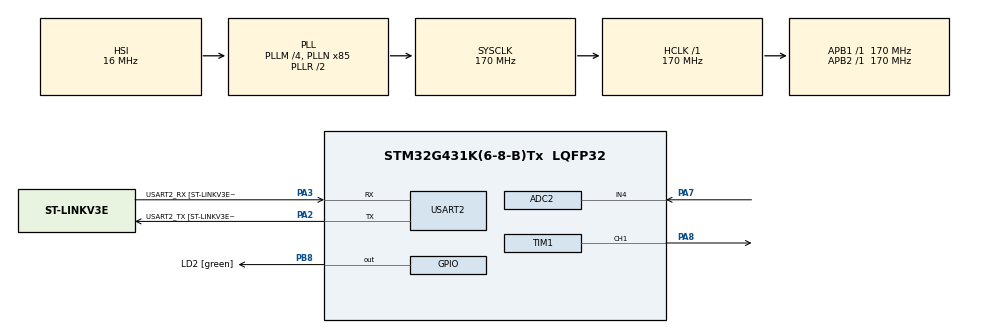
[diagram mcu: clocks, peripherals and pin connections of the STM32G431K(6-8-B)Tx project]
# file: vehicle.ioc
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ADC2.Channel-0\#ChannelRegularConversion=ADC_CHANNEL_4
ADC2.ClockPrescaler=ADC_CLOCK_ASYNC_DIV256
ADC2.ContinuousConvMode=ENABLE
ADC2.ExternalTrigConv=ADC_EXTERNALTRIG_T1_TRGO
ADC2.ExternalTrigConvEdge=ADC_EXTERNALTRIGCONVEDGE_FALLING
ADC2.NbrOfConversionFlag=1
ADC2.OffsetNumber-0\#ChannelRegularConversion=ADC_OFFSET_NONE
ADC2.Rank-0\#ChannelRegularConversion=1
ADC2.SamplingTime-0\#ChannelRegularConversion=ADC_SAMPLETIME_2CYCLES_5
Mcu.Family=STM32G4
Mcu.Name=STM32G431K(6-8-B)Tx
Mcu.Package=LQFP32
NVIC.PriorityGroup=NVIC_PRIORITYGROUP_4
PA13.GPIO_Label=T_SWDIO
PA13.Mode=Serial_Wire
PA13.Signal=SYS_JTMS-SWDIO
PA14.GPIO_Label=T_SWCLK
PA14.Mode=Serial_Wire
PA14.Signal=SYS_JTCK-SWCLK
PA2.GPIO_Label=USART2_TX [ST-LINKV3E_VCP_RX]
PA2.Mode=Asynchronous
PA2.Signal=USART2_TX
PA3.GPIO_Label=USART2_RX [ST-LINKV3E_VCP_TX]
PA3.Mode=Asynchronous
PA3.Signal=USART2_RX
PA7.Mode=IN4-Single-Ended
PA7.Signal=ADC2_IN4
PA8.Signal=S_TIM1_CH1
PB3.GPIO_Label=T_SWO
PB3.Signal=SYS_JTDO-SWO
PB8-BOOT0.GPIO_Label=LD2 [green]
PB8-BOOT0.Signal=GPIO_Output
PF0-OSC_IN.Mode=HSE-External-Oscillator
PF0-OSC_IN.Signal=RCC_OSC_IN
PF1-OSC_OUT.Mode=HSE-External-Oscillator
PF1-OSC_OUT.Signal=RCC_OSC_OUT
ProjectManager.HeapSize=0x200
ProjectManager.StackSize=0x400
ProjectManager.TargetToolchain=STM32CubeIDE
RCC.ADC12Freq_Value=170000000
RCC.AHBFreq_Value=170000000
RCC.APB1Freq_Value=170000000
RCC.APB1TimFreq_Value=170000000
RCC.APB2Freq_Value=170000000
RCC.APB2TimFreq_Value=170000000
RCC.CortexFreq_Value=170000000
RCC.EXTERNAL_CLOCK_VALUE=12288000
RCC.HCLKFreq_Value=170000000
RCC.HSE_VALUE=8000000
RCC.HSI48_VALUE=48000000
RCC.HSI_VALUE=16000000
RCC.LSE_VALUE=32768
RCC.PLLM=RCC_PLLM_DIV4
RCC.PLLN=85
RCC.SYSCLKFreq_VALUE=170000000
RCC.SYSCLKSource=RCC_SYSCLKSOURCE_PLLCLK
RCC.USBFreq_Value=170000000
RCC.VCOOutputFreq_Value=340000000
SH.S_TIM1_CH1.0=TIM1_CH1,PWM Generation1 CH1
TIM1.AutoReloadPreload=TIM_AUTORELOAD_PRELOAD_ENABLE
TIM1.Channel-PWM\ Generation1\ CH1=TIM_CHANNEL_1
TIM1.Channel-PWM\ Generation2\ No\ Output=TIM_CHANNEL_2
TIM1.PeriodNoDither=100-1
TIM1.Prescaler=170
TIM1.TIM_MasterOutputTrigger=TIM_TRGO_UPDATE
USART2.VirtualMode-Asynchronous=VM_ASYNC
USART2.WordLength=WORDLENGTH_8B
VP_TIM1_VS_ClockSourceINT.Mode=Internal
VP_TIM1_VS_no_output2.Mode=PWM Generation2 No Output
VP_TIM2_VS_ClockSourceITR.Mode=TriggerSource_ITR0
VP_TIM2_VS_ControllerModeTrigger.Mode=Trigger Mode
board=NUCLEO-G431KB

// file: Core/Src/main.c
/* USER CODE BEGIN Header */
/**
  ******************************************************************************
  * @file           : main.c
  * @brief          : Main program body
  ******************************************************************************
  * @attention
  *
  * Copyright (c) 2023 STMicroelectronics.
  * All rights reserved.
  *
  * This software is licensed under terms that can be found in the LICENSE file
  * in the root directory of this software component.
  * If no LICENSE file comes with this software, it is provided AS-IS.
  *
  ******************************************************************************
  */
/* USER CODE END Header */
#include "main.h"
#include "adc.h"
#include "tim.h"
#include "usart.h"
#include "gpio.h"

/* USER CODE BEGIN Includes */
#include "vehicle/vehicle.h"

/* USER CODE END Includes */

void SystemClock_Config(void);

int main(void)
{

  /* MCU Configuration--------------------------------------------------------*/

  /* Reset of all peripherals, Initializes the Flash interface and the Systick. */
  HAL_Init();

  /* Configure the system clock */
  SystemClock_Config();

  /* Initialize all configured peripherals */
  MX_GPIO_Init();
  MX_USART2_UART_Init();
  MX_ADC2_Init();
  MX_TIM1_Init();
  MX_TIM2_Init();
  /* USER CODE BEGIN 2 */
  vehicle_init();
  /* USER CODE END 2 */

  /* Infinite loop */
  while (1)
  {

    /* USER CODE BEGIN 3 */
    vehicle_update();
  }
  /* USER CODE END 3 */
}

void SystemClock_Config(void)
{
  RCC_OscInitTypeDef RCC_OscInitStruct = {0};
  RCC_ClkInitTypeDef RCC_ClkInitStruct = {0};

  /** Configure the main internal regulator output voltage
  */
  HAL_PWREx_ControlVoltageScaling(PWR_REGULATOR_VOLTAGE_SCALE1_BOOST);

  /** Initializes the RCC Oscillators according to the specified parameters
  * in the RCC_OscInitTypeDef structure.
  */
  RCC_OscInitStruct.OscillatorType = RCC_OSCILLATORTYPE_HSI;
  RCC_OscInitStruct.HSIState = RCC_HSI_ON;
  RCC_OscInitStruct.HSICalibrationValue = RCC_HSICALIBRATION_DEFAULT;
  RCC_OscInitStruct.PLL.PLLState = RCC_PLL_ON;
  RCC_OscInitStruct.PLL.PLLSource = RCC_PLLSOURCE_HSI;
  RCC_OscInitStruct.PLL.PLLM = RCC_PLLM_DIV4;
  RCC_OscInitStruct.PLL.PLLN = 85;
  RCC_OscInitStruct.PLL.PLLP = RCC_PLLP_DIV2;
  RCC_OscInitStruct.PLL.PLLQ = RCC_PLLQ_DIV2;
  RCC_OscInitStruct.PLL.PLLR = RCC_PLLR_DIV2;
  if (HAL_RCC_OscConfig(&RCC_OscInitStruct) != HAL_OK)
  {
    Error_Handler();
  }

  /** Initializes the CPU, AHB and APB buses clocks
  */
  RCC_ClkInitStruct.ClockType = RCC_CLOCKTYPE_HCLK|RCC_CLOCKTYPE_SYSCLK
                              |RCC_CLOCKTYPE_PCLK1|RCC_CLOCKTYPE_PCLK2;
  RCC_ClkInitStruct.SYSCLKSource = RCC_SYSCLKSOURCE_PLLCLK;
  RCC_ClkInitStruct.AHBCLKDivider = RCC_SYSCLK_DIV1;
  RCC_ClkInitStruct.APB1CLKDivider = RCC_HCLK_DIV1;
  RCC_ClkInitStruct.APB2CLKDivider = RCC_HCLK_DIV1;

  if (HAL_RCC_ClockConfig(&RCC_ClkInitStruct, FLASH_LATENCY_4) != HAL_OK)
  {
    Error_Handler();
  }
}

void Error_Handler(void)
{
  __disable_irq();
  while (1)
  {
  }
}
